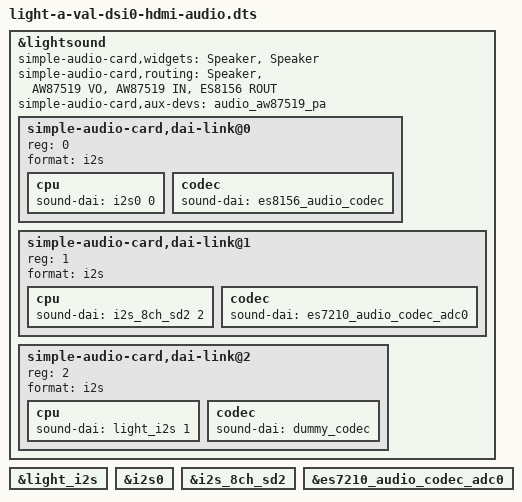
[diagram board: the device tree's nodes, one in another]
/* SPDX-License-Identifier: GPL-2.0 */
/*
 * Copyright (C) 2021 Alibaba Group Holding Limited.
 */

/dts-v1/;

#include "light-a-val-dsi0-hdmi.dts"

&lightsound {
        status = "okay";
        simple-audio-card,widgets = "Speaker", "Speaker";
        simple-audio-card,routing = 
        	"Speaker", "AW87519 VO",
        	"AW87519 IN", "ES8156 ROUT";
        simple-audio-card,aux-devs = <&audio_aw87519_pa>;
        simple-audio-card,dai-link@0 {          /* I2S - AUDIO SYS CODEC 8156*/
                reg = <0>;
                format = "i2s";
                cpu {
                        sound-dai = <&i2s0 0>;
                };
                codec {
                        sound-dai = <&es8156_audio_codec>;
                };
        };

        simple-audio-card,dai-link@1 {          /* I2S - AUDIO SYS CODEC 7210*/
                reg = <1>;
                format = "i2s";
                cpu {
                        sound-dai = <&i2s_8ch_sd2 2>;
                };
                codec {
                        sound-dai = <&es7210_audio_codec_adc0>;
                };
        };
        simple-audio-card,dai-link@2 {          /* I2S - HDMI */
                reg = <2>;
                format = "i2s";
                cpu {
                        sound-dai = <&light_i2s 1>;
                };
                codec {
                        sound-dai = <&dummy_codec>;
                };
        };
};

&light_i2s {
	status = "okay";
};

&i2s0 {
        status = "okay";
};

&i2s_8ch_sd2 {
        status = "okay";
};

&es7210_audio_codec_adc0 {
        status = "okay";
};
